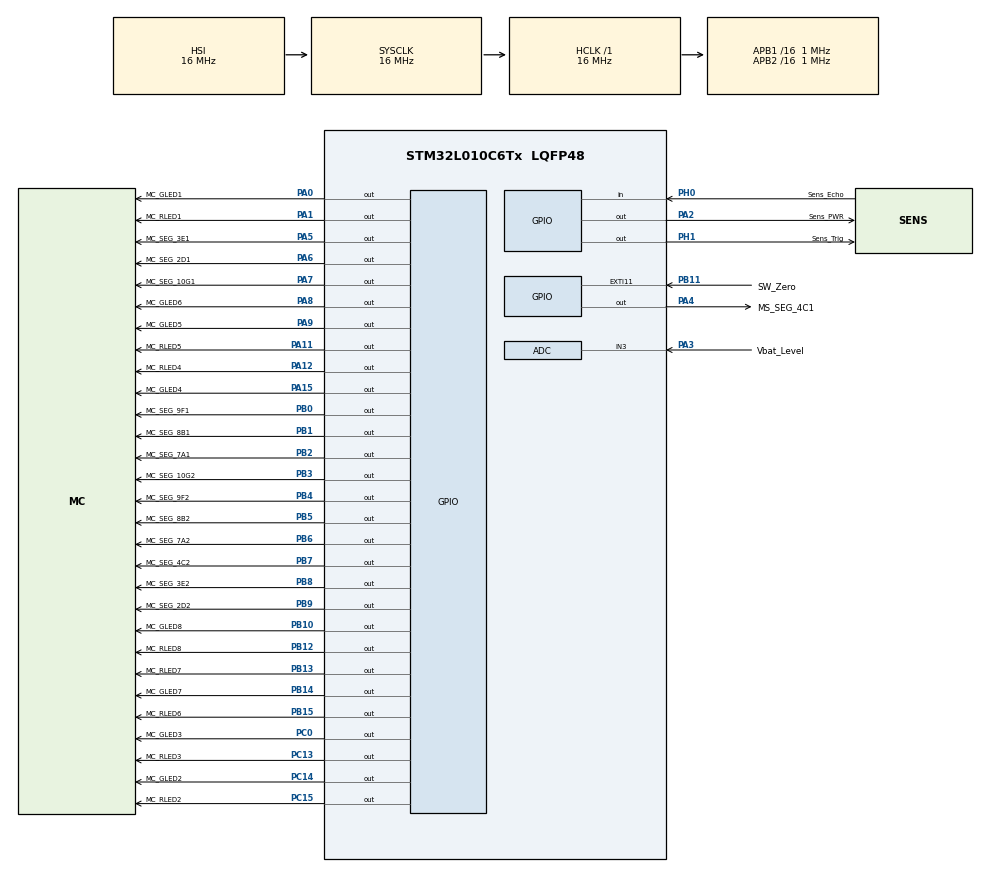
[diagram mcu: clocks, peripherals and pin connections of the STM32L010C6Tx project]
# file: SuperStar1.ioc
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ADC.ClockPrescaler=ADC_CLOCK_ASYNC_DIV4
ADC.LowPowerAutoPowerOff=DISABLE
ADC.LowPowerAutoWait=DISABLE
ADC.LowPowerFrequencyMode=DISABLE
ADC.Overrun=ADC_OVR_DATA_OVERWRITTEN
ADC.OversamplingMode=DISABLE
ADC.Resolution=ADC_RESOLUTION_10B
ADC.SamplingTime=ADC_SAMPLETIME_160CYCLES_5
LPTIM1.ClockPrescaler=LPTIM_PRESCALER_DIV32
Mcu.Family=STM32L0
Mcu.Name=STM32L010C6Tx
Mcu.Package=LQFP48
NVIC.EXTI4_15_IRQn=true\:0\:0\:false\:false\:true\:true\:true
NVIC.LPTIM1_IRQn=true\:2\:0\:true\:false\:true\:true\:true
NVIC.TIM2_IRQn=true\:1\:0\:true\:false\:true\:true\:true
PA0.GPIO_Label=MC_GLED1
PA0.GPIO_PuPd=GPIO_PULLDOWN
PA0.Signal=GPIO_Output
PA1.GPIO_Label=MC_RLED1
PA1.GPIO_PuPd=GPIO_PULLDOWN
PA1.Signal=GPIO_Output
PA11.GPIO_Label=MC_RLED5
PA11.GPIO_PuPd=GPIO_PULLDOWN
PA11.Signal=GPIO_Output
PA12.GPIO_Label=MC_RLED4
PA12.GPIO_PuPd=GPIO_PULLDOWN
PA12.Signal=GPIO_Output
PA13.GPIO_Label=SW_DIO
PA13.Mode=Serial_Wire
PA13.Signal=SYS_SWDIO
PA14.GPIO_Label=SW_CLK
PA14.Mode=Serial_Wire
PA14.Signal=SYS_SWCLK
PA15.GPIO_Label=MC_GLED4
PA15.GPIO_PuPd=GPIO_PULLDOWN
PA15.Signal=GPIO_Output
PA2.GPIO_Label=Sens_PWR
PA2.GPIO_PuPd=GPIO_PULLDOWN
PA2.Signal=GPIO_Output
PA3.GPIO_Label=Vbat_Level
PA3.Mode=IN3
PA3.Signal=ADC_IN3
PA4.GPIO_Label=MS_SEG_4C1
PA4.GPIO_PuPd=GPIO_PULLDOWN
PA4.Signal=GPIO_Output
PA5.GPIO_Label=MC_SEG_3E1
PA5.GPIO_PuPd=GPIO_PULLDOWN
PA5.Signal=GPIO_Output
PA6.GPIO_Label=MC_SEG_2D1
PA6.GPIO_PuPd=GPIO_PULLDOWN
PA6.Signal=GPIO_Output
PA7.GPIO_Label=MC_SEG_10G1
PA7.GPIO_PuPd=GPIO_PULLDOWN
PA7.Signal=GPIO_Output
PA8.GPIO_Label=MC_GLED6
PA8.GPIO_PuPd=GPIO_PULLDOWN
PA8.Signal=GPIO_Output
PA9.GPIO_Label=MC_GLED5
PA9.GPIO_PuPd=GPIO_PULLDOWN
PA9.Signal=GPIO_Output
PB0.GPIO_Label=MC_SEG_9F1
PB0.GPIO_PuPd=GPIO_PULLDOWN
PB0.Signal=GPIO_Output
PB1.GPIO_Label=MC_SEG_8B1
PB1.GPIO_PuPd=GPIO_PULLDOWN
PB1.Signal=GPIO_Output
PB10.GPIO_Label=MC_GLED8
PB10.GPIO_PuPd=GPIO_PULLDOWN
PB10.Signal=GPIO_Output
PB11.GPIO_Label=SW_Zero
PB11.GPIO_ModeDefaultEXTI=GPIO_MODE_IT_RISING
PB11.Signal=GPXTI11
PB12.GPIO_Label=MC_RLED8
PB12.GPIO_PuPd=GPIO_PULLDOWN
PB12.Signal=GPIO_Output
PB13.GPIO_Label=MC_RLED7
PB13.GPIO_PuPd=GPIO_PULLDOWN
PB13.Signal=GPIO_Output
PB14.GPIO_Label=MC_GLED7
PB14.GPIO_PuPd=GPIO_PULLDOWN
PB14.Signal=GPIO_Output
PB15.GPIO_Label=MC_RLED6
PB15.GPIO_PuPd=GPIO_PULLDOWN
PB15.Signal=GPIO_Output
PB2.GPIO_Label=MC_SEG_7A1
PB2.GPIO_PuPd=GPIO_PULLDOWN
PB2.Signal=GPIO_Output
PB3.GPIO_Label=MC_SEG_10G2
PB3.GPIO_PuPd=GPIO_PULLDOWN
PB3.Signal=GPIO_Output
PB4.GPIO_Label=MC_SEG_9F2
PB4.GPIO_PuPd=GPIO_PULLDOWN
PB4.Signal=GPIO_Output
PB5.GPIO_Label=MC_SEG_8B2
PB5.GPIO_PuPd=GPIO_PULLDOWN
PB5.Signal=GPIO_Output
PB6.GPIO_Label=MC_SEG_7A2
PB6.GPIO_PuPd=GPIO_PULLDOWN
PB6.Signal=GPIO_Output
PB7.GPIO_Label=MC_SEG_4C2
PB7.GPIO_PuPd=GPIO_PULLDOWN
PB7.Signal=GPIO_Output
PB8.GPIO_Label=MC_SEG_3E2
PB8.GPIO_PuPd=GPIO_PULLDOWN
PB8.Signal=GPIO_Output
PB9.GPIO_Label=MC_SEG_2D2
PB9.GPIO_PuPd=GPIO_PULLDOWN
PB9.Signal=GPIO_Output
PC0.GPIO_Label=MC_GLED3
PC0.GPIO_PuPd=GPIO_PULLDOWN
PC0.Signal=GPIO_Output
PC13-ANTI_TAMP.GPIO_Label=MC_RLED3
PC13-ANTI_TAMP.GPIO_PuPd=GPIO_PULLDOWN
PC13-ANTI_TAMP.Signal=GPIO_Output
PC14-OSC32_IN.GPIO_Label=MC_GLED2
PC14-OSC32_IN.GPIO_PuPd=GPIO_PULLDOWN
PC14-OSC32_IN.PinState=GPIO_PIN_RESET
PC14-OSC32_IN.Signal=GPIO_Output
PC15-OSC32_OUT.GPIO_Label=MC_RLED2
PC15-OSC32_OUT.GPIO_PuPd=GPIO_PULLDOWN
PC15-OSC32_OUT.PinState=GPIO_PIN_RESET
PC15-OSC32_OUT.Signal=GPIO_Output
PH0-OSC_IN.GPIO_Label=Sens_Echo
PH0-OSC_IN.GPIO_PuPd=GPIO_NOPULL
PH0-OSC_IN.Signal=GPIO_Input
PH1-OSC_OUT.GPIO_Label=Sens_Trig
PH1-OSC_OUT.GPIO_PuPd=GPIO_PULLDOWN
PH1-OSC_OUT.Signal=GPIO_Output
ProjectManager.HeapSize=0x400
ProjectManager.StackSize=0x800
ProjectManager.TargetToolchain=TrueSTUDIO
RCC.ADCFreq_Value=16000000
RCC.AHBFreq_Value=16000000
RCC.APB1CLKDivider=RCC_HCLK_DIV16
RCC.APB1Freq_Value=1000000
RCC.APB1TimFreq_Value=2000000
RCC.APB2CLKDivider=RCC_HCLK_DIV16
RCC.APB2Freq_Value=1000000
RCC.APB2TimFreq_Value=2000000
RCC.HCLKFreq_Value=16000000
RCC.HSE_VALUE=8000000
RCC.HSI16_VALUE=16000000
RCC.HSI_VALUE=16000000
RCC.LSE_VALUE=32768
RCC.LptimClockSelection=RCC_LPTIM1CLKSOURCE_LSI
RCC.MSIClockRange=RCC_MSIRANGE_0
RCC.MSI_VALUE=65536
RCC.SYSCLKFreq_VALUE=16000000
RCC.SYSCLKSource=RCC_SYSCLKSOURCE_HSI
RCC.VCOOutputFreq_Value=48000000
TIM2.AutoReloadPreload=TIM_AUTORELOAD_PRELOAD_DISABLE
TIM2.Period=99
TIM2.Prescaler=1
VP_LPTIM1_VS_LPTIM_counterModeInternalClock.Mode=Counts__internal_clock_event_00
VP_RTC_VS_RTC_Activate.Mode=RTC_Enabled
VP_RTC_VS_RTC_WakeUp_intern.Mode=WakeUp
VP_TIM2_VS_ClockSourceINT.Mode=Internal
board=custom

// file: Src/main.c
/* USER CODE BEGIN Header */
/**
  ******************************************************************************
  * @file           : main.c
  * @brief          : Main program body
  ******************************************************************************
  * @attention
  *
  * <h2><center>&copy; Copyright (c) 2020 STMicroelectronics.
  * All rights reserved.</center></h2>
  *
  * This software component is licensed by ST under BSD 3-Clause license,
  * the "License"; You may not use this file except in compliance with the
  * License. You may obtain a copy of the License at:
  *                        opensource.org/licenses/BSD-3-Clause
  *
  ******************************************************************************
  */
/* USER CODE END Header */

#include "main.h"
#include "adc.h"
#include "lptim.h"
#include "rtc.h"
#include "tim.h"
#include "gpio.h"

/* USER CODE BEGIN Includes */
#include"MainSupport.h"
/*
#include "LED_Control.h"
#include "BatteryMonitor.h"
#include "stm32l0xx_hal_adc_ex.h"
*/

/* USER CODE END Includes */

void SystemClock_Config(void);

int main(void)
{

  /* MCU Configuration--------------------------------------------------------*/

  /* Reset of all peripherals, Initializes the Flash interface and the Systick. */
  HAL_Init();

  /* Configure the system clock */
  SystemClock_Config();

  /* Initialize all configured peripherals */
  MX_GPIO_Init();
  MX_ADC_Init();
  MX_LPTIM1_Init();
  MX_TIM2_Init();
  MX_RTC_Init();
  /* USER CODE BEGIN 2 */
  main_Init();

  //while(HAL_ADCEx_Calibration_Start(&hadc, ADC_SINGLE_ENDED) != HAL_OK);

  /* USER CODE END 2 */

  /* Infinite loop */
  /* USER CODE BEGIN WHILE */
  while(1)
  {
	  main_WhileLoop();

    /* USER CODE END WHILE */

  }
}

void SystemClock_Config(void)
{
  RCC_OscInitTypeDef RCC_OscInitStruct = {0};
  RCC_ClkInitTypeDef RCC_ClkInitStruct = {0};
  RCC_PeriphCLKInitTypeDef PeriphClkInit = {0};

  /** Configure the main internal regulator output voltage
  */
  __HAL_PWR_VOLTAGESCALING_CONFIG(PWR_REGULATOR_VOLTAGE_SCALE1);
  /** Initializes the CPU, AHB and APB busses clocks
  */
  RCC_OscInitStruct.OscillatorType = RCC_OSCILLATORTYPE_HSI|RCC_OSCILLATORTYPE_LSI;
  RCC_OscInitStruct.HSIState = RCC_HSI_ON;
  RCC_OscInitStruct.HSICalibrationValue = RCC_HSICALIBRATION_DEFAULT;
  RCC_OscInitStruct.LSIState = RCC_LSI_ON;
  RCC_OscInitStruct.PLL.PLLState = RCC_PLL_NONE;
  if (HAL_RCC_OscConfig(&RCC_OscInitStruct) != HAL_OK)
  {
    Error_Handler();
  }
  /** Initializes the CPU, AHB and APB busses clocks
  */
  RCC_ClkInitStruct.ClockType = RCC_CLOCKTYPE_HCLK|RCC_CLOCKTYPE_SYSCLK
                              |RCC_CLOCKTYPE_PCLK1|RCC_CLOCKTYPE_PCLK2;
  RCC_ClkInitStruct.SYSCLKSource = RCC_SYSCLKSOURCE_HSI;
  RCC_ClkInitStruct.AHBCLKDivider = RCC_SYSCLK_DIV1;
  RCC_ClkInitStruct.APB1CLKDivider = RCC_HCLK_DIV16;
  RCC_ClkInitStruct.APB2CLKDivider = RCC_HCLK_DIV16;

  if (HAL_RCC_ClockConfig(&RCC_ClkInitStruct, FLASH_LATENCY_0) != HAL_OK)
  {
    Error_Handler();
  }
  PeriphClkInit.PeriphClockSelection = RCC_PERIPHCLK_RTC|RCC_PERIPHCLK_LPTIM1;
  PeriphClkInit.RTCClockSelection = RCC_RTCCLKSOURCE_LSI;
  PeriphClkInit.LptimClockSelection = RCC_LPTIM1CLKSOURCE_LSI;

  if (HAL_RCCEx_PeriphCLKConfig(&PeriphClkInit) != HAL_OK)
  {
    Error_Handler();
  }
}

void Error_Handler(void)
{
  /* USER CODE BEGIN Error_Handler_Debug */
  /* User can add his own implementation to report the HAL error return state */
	// TODO: Trinks add code here to call our Error Handler

  /* USER CODE END Error_Handler_Debug */
}

/************************ (C) COPYRIGHT STMicroelectronics *****END OF FILE****/
